# GD32H77x_78x register map
File version: 1.0
CPU: CM7 r1p2, little endian, MPU, FPU, 4 interrupt priority bits
Registers are 32-bit, read-write, reset 0x0 unless marked. A register's access mark holds for its fields unless they carry their own. Offsets are from the block's base; [hi:lo] are bit positions; {n}, {i} and the like mark numbered series; 'fields as' and 'values as' point back to an identical list.

## FFT — Fast Fourier Transform
Base 0x48024000
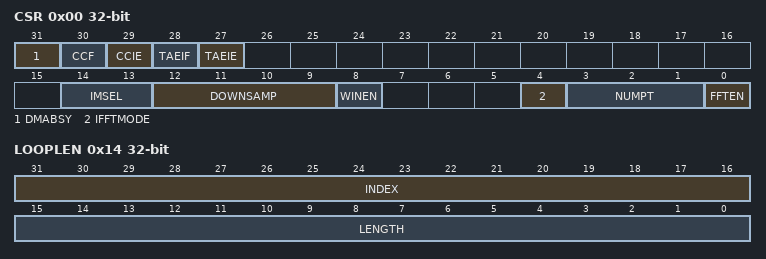
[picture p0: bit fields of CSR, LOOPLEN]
0x00 CSR access per field — Control and status register
  [31] DMABSY ro — DMA Busy
  [30] CCF rw — FFT calculation completion flag
  [29] CCIE rw — FFT calculation completion interrupt enable
  [28] TAEIF rw — Transfer access error interrupt flag
  [27] TAEIE rw — Transfer access error interrupt enable
  [14:13] IMSEL rw — Image input source select
  [12:9] DOWNSAMP rw — Input data down sample selection
  [8] WINEN rw — Window function enable
  [4] IFFTMODE rw — IFFT mode enable
  [3:1] NUMPT rw — Number of FFT Point
  [0] FFTEN rw — FFT enable
0x04 RESADDR — Real start address registe
  [31:0] RESADDR — FFT real start address
0x08 IMSADDR — Image start address register
  [31:0] IMSADDR — FFT image start address
0x0C WSADDR — Window start address register
  [31:0] FFT_WSADDR — FFT window start address
0x10 OSADDR — Output start address register
  [31:0] FFT_OSADDR — FFT output start address
0x14 LOOPLEN — Loop length register
  [31:16] INDEX — The index of DMA loop buffer
  [15:0] LENGTH — The DMA loop buffer length of the FFT input data.

## FWDGT — free watchdog timer
Base 0x58004800
0x00 CTL wo — Control register
  [15:0] CMD — Key value
0x04 PSC — Prescaler register
  [2:0] PSC — Prescaler divider
0x08 RLD reset 0xFFF — Reload register
  [11:0] RLD — Watchdog counter reload value
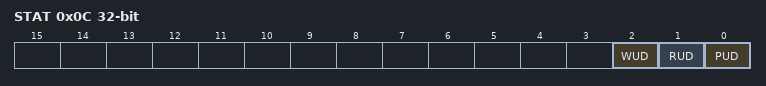
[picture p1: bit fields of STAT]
0x0C STAT ro — Status register
  [2] WUD — Watchdog counter window value update
  [1] RUD — Watchdog counter reload value update
  [0] PUD — Watchdog prescaler value update
0x10 WND reset 0xFFF — Window register
  [11:0] WND — Watchdog counter window value

## GPIOA — General-purpose I/Os
Base 0x58020000
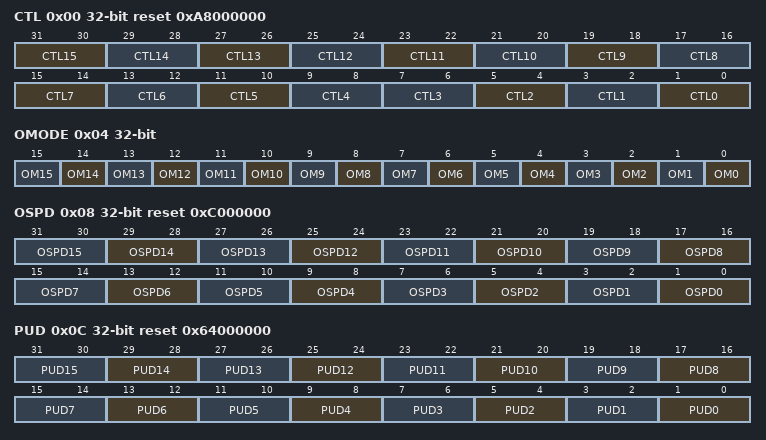
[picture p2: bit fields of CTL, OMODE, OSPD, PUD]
0x00 CTL reset 0xA8000000 — GPIO port control register
  [2n+1:2n] CTL{n} (n=7..15) — Port x configuration bits (x = {n})
  [13:12] CTL6 — Port x configuration bits (x = 6 )
  [11:10] CTL5 — Port x configuration bits (x = 5)
  [9:8] CTL4 — Port x configuration bits (x = 4 )
  [2n+1:2n] CTL{n} (n=0..3) — Port x configuration bits (x = {n})
0x04 OMODE — GPIO port output mode register
  [n] OM{n} (n=0..15) — Port {n} output mode bit
0x08 OSPD reset 0xC000000 — GPIO port output speed register
  [2n+1:2n] OSPD{n} (n=0..15) — Port {n} output max speed bits
0x0C PUD reset 0x64000000 — GPIO port pull-up/pull-down register
  [2n+1:2n] PUD{n} (n=0..15) — Port {n} pull-up or pull-down bits
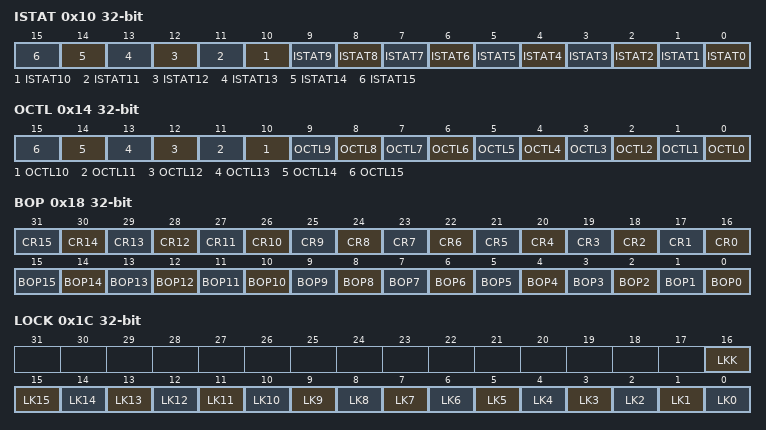
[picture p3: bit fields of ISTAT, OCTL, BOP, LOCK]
0x10 ISTAT ro — GPIO port input status register
  [n] ISTAT{n} (n=0..15) — Port input status (y = {n})
0x14 OCTL — GPIO port output control register
  [n] OCTL{n} (n=0..15) — Port output control (y = {n})
0x18 BOP wo — GPIO port bit operate register
  [n+16] CR{n} (n=0..15) — Port Clear bit {n}
  [n] BOP{n} (n=0..15) — Port Set bit {n}
0x1C LOCK — GPIO port configuration lock register
  [16] LKK — Lock sequence key
  [n] LK{n} (n=0..15) — Port Lock bit {n}
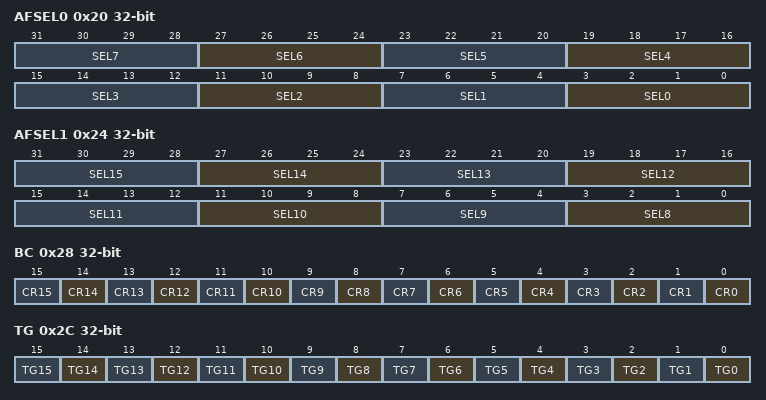
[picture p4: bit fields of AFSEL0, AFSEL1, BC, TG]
0x20 AFSEL0 — GPIO alternate function selected register 0
  [4n+3:4n] SEL{n} (n=0..7) — Port {n} alternate function selected
0x24 AFSEL1 — GPIO alternate function selected register 1
  [4n-29:4n-32] SEL{n} (n=8..15) — Port {n} alternate function selected
0x28 BC wo — Bit clear register
  [n] CR{n} (n=0..15) — Port cleat bit
0x2C TG wo — Port bit toggle register
  [n] TG{n} (n=0..15) — Port toggle bit
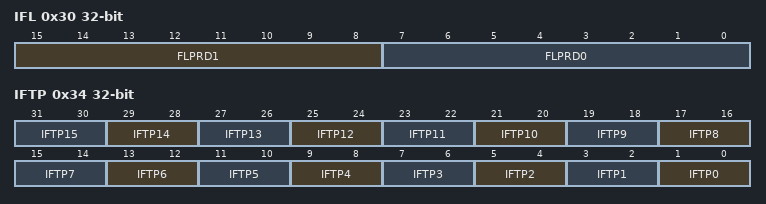
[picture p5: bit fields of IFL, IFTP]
0x30 IFL — Input filtering regist
  [15:8] FLPRD1 — Filter sampling period for GPIO8 to GPIO15:
  [7:0] FLPRD0 — Filter sampling period for GPIO1 to GPIO7:
0x34 IFTP — Input filtering type regist
  [2n+1:2n] IFTP{n} (n=0..15) — Pin {n} input filtering type bits

## GPIOB — General-purpose I/Os
Base 0x58020400
Registers as GPIOA; these are added or differ:
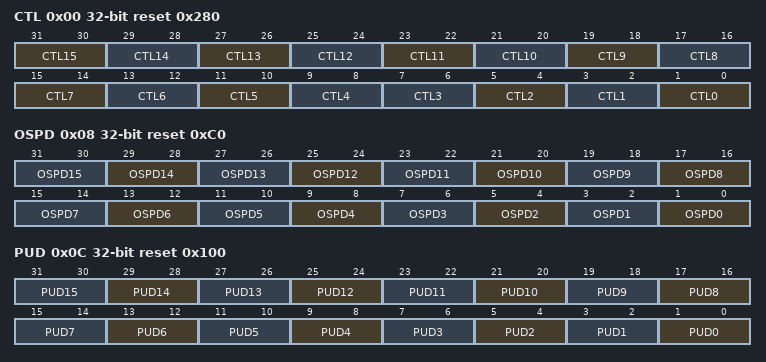
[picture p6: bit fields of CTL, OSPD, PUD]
0x00 CTL reset 0x280 — GPIO port control register
  fields as GPIOA.CTL
0x08 OSPD reset 0xC0 — GPIO port output speed register
  [2n+1:2n] OSPD{n} (n=0..15) — Port {n} output max speed bits
0x0C PUD reset 0x100 — GPIO port pull-up/pull-down register
  [2n+1:2n] PUD{n} (n=0..15) — Port {n} pull-up or pull-down bits

## GPIOC — General-purpose I/Os
Base 0x58020800
Same registers: GPIOD 0x58020C00, GPIOE 0x58021000, GPIOF 0x58021400, GPIOG 0x58021800, GPIOH 0x58021C00, GPIOJ 0x58022400, GPIOK 0x58022800
Registers as GPIOA; these are added or differ:
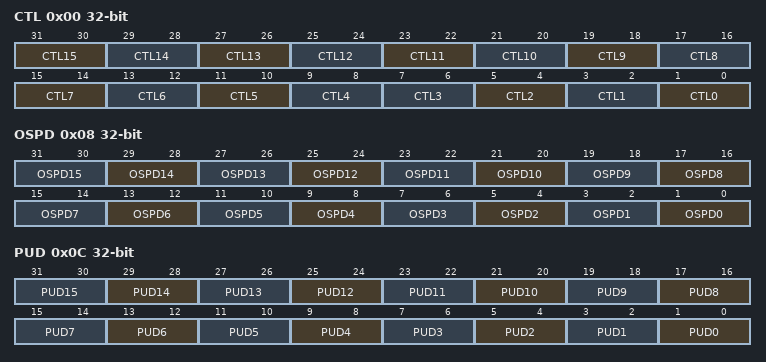
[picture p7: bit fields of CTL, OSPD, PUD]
0x00 CTL — GPIO port control register
  fields as GPIOA.CTL
0x08 OSPD — GPIO port output speed register
  [2n+1:2n] OSPD{n} (n=0..15) — Port {n} output max speed bits
0x0C PUD — GPIO port pull-up/pull-down register
  [2n+1:2n] PUD{n} (n=0..15) — Port {n} pull-up or pull-down bits
